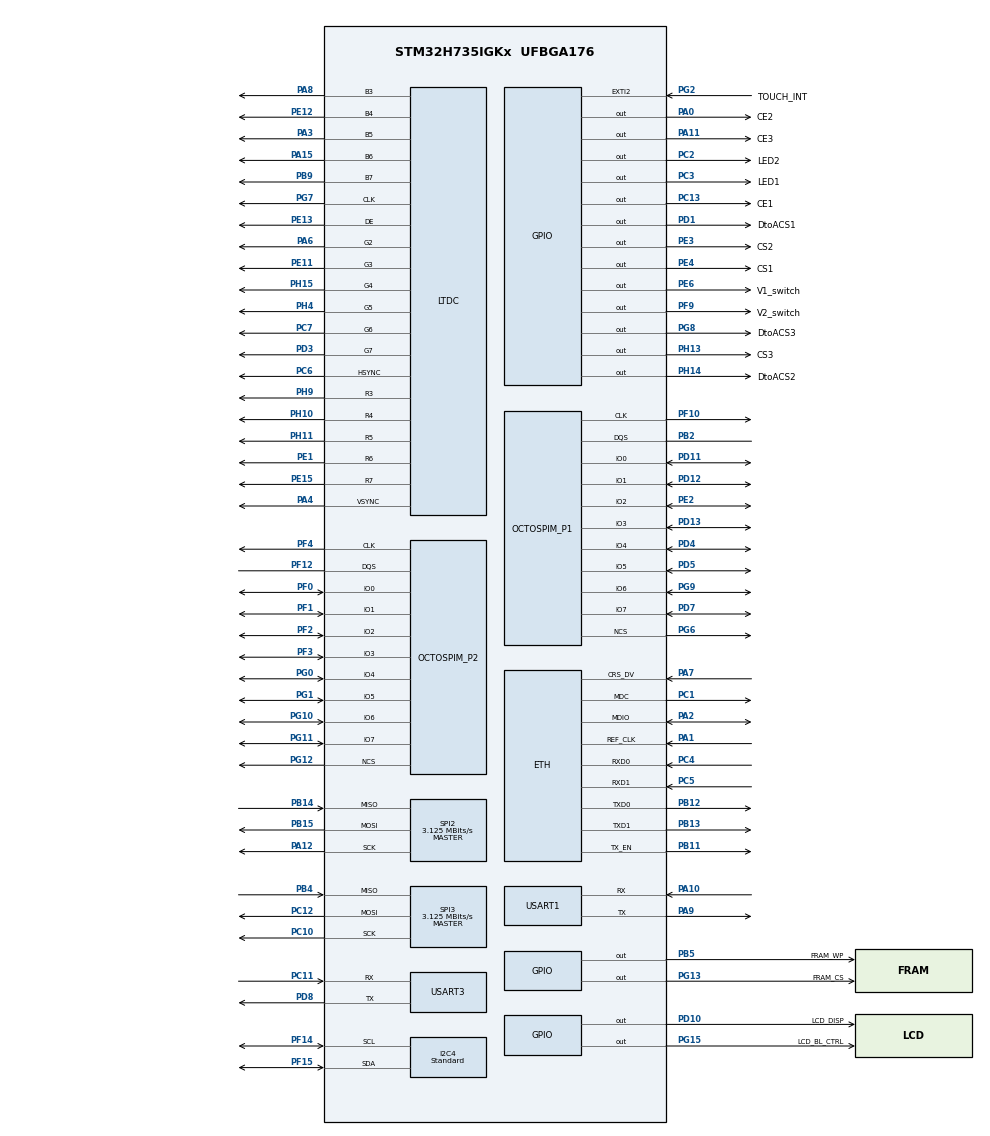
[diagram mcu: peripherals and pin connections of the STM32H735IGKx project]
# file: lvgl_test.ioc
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CORTEX_M7.AccessPermission-Cortex_Memory_Protection_Unit_Region1_Settings=MPU_REGION_FULL_ACCESS
CORTEX_M7.AccessPermission-Cortex_Memory_Protection_Unit_Region2_Settings=MPU_REGION_FULL_ACCESS
CORTEX_M7.BaseAddress-Cortex_Memory_Protection_Unit_Region1_Settings=0x30000000
CORTEX_M7.BaseAddress-Cortex_Memory_Protection_Unit_Region2_Settings=0x30000000
CORTEX_M7.CPU_DCache=Enabled
CORTEX_M7.CPU_ICache=Enabled
CORTEX_M7.DisableExec-Cortex_Memory_Protection_Unit_Region1_Settings=MPU_INSTRUCTION_ACCESS_DISABLE
CORTEX_M7.DisableExec-Cortex_Memory_Protection_Unit_Region2_Settings=MPU_INSTRUCTION_ACCESS_DISABLE
CORTEX_M7.Enable-Cortex_Memory_Protection_Unit_Region0_Settings=__NULL
CORTEX_M7.Enable-Cortex_Memory_Protection_Unit_Region1_Settings=MPU_REGION_ENABLE
CORTEX_M7.Enable-Cortex_Memory_Protection_Unit_Region2_Settings=MPU_REGION_ENABLE
CORTEX_M7.IsBufferable-Cortex_Memory_Protection_Unit_Region1_Settings=MPU_ACCESS_NOT_BUFFERABLE
CORTEX_M7.IsBufferable-Cortex_Memory_Protection_Unit_Region2_Settings=MPU_ACCESS_BUFFERABLE
CORTEX_M7.IsShareable-Cortex_Memory_Protection_Unit_Region1_Settings=MPU_ACCESS_NOT_SHAREABLE
CORTEX_M7.IsShareable-Cortex_Memory_Protection_Unit_Region2_Settings=MPU_ACCESS_SHAREABLE
CORTEX_M7.MPU_Control=MPU_PRIVILEGED_DEFAULT
CORTEX_M7.Size-Cortex_Memory_Protection_Unit_Region1_Settings=MPU_REGION_SIZE_32KB
CORTEX_M7.Size-Cortex_Memory_Protection_Unit_Region2_Settings=MPU_REGION_SIZE_512B
CORTEX_M7.TypeExtField-Cortex_Memory_Protection_Unit_Region1_Settings=MPU_TEX_LEVEL1
DMA2D.ColorMode=DMA2D_OUTPUT_RGB565
DMA2D.InputColorModeForeground=DMA2D_INPUT_RGB565
DMA2D.Mode=DMA2D_M2M
ETH.MediaInterface=HAL_ETH_RMII_MODE
ETH.RxBuffAddress=0x30000100
ETH.RxBuffLen=1536
ETH.TxDescAddress=0x30000100
FREERTOS.Tasks01=defaultTask,24,1024,StartDefaultTask,Default,NULL,Dynamic,NULL,NULL
FREERTOS.configTOTAL_HEAP_SIZE=100000
FREERTOS.configUSE_NEWLIB_REENTRANT=1
I2C4.I2C_Speed_Mode=I2C_Standard
I2C4.Timing=0x60404E72
LTDC.ActiveH=272
LTDC.ActiveW=480
LTDC.Alpha_L0=255
LTDC.FBStartAdress_L0=0x70000000
LTDC.HBP=13
LTDC.HFP=32
LTDC.HSync=41
LTDC.ImageHeight_L0=272
LTDC.ImageWidth_L0=480
LTDC.Layers=0
LTDC.PixelFormat_L0=LTDC_PIXEL_FORMAT_RGB565
LTDC.VSync=10
LTDC.WindowX1_L0=480
LTDC.WindowY1_L0=272
LWIP.BSP.number=1
LWIP.IP_ADDRESS=192.168.000.010
LWIP.LWIP_DHCP=0
LWIP.LWIP_RAM_HEAP_POINTER=0x30000200
LWIP.MEMP_NUM_TCP_SEG=17
LWIP.MEM_SIZE=32232
LWIP.NETMASK_ADDRESS=255.255.255.000
LWIP.TCP_MSS=1460
LWIP.TCP_SND_BUF=5840
LWIP.TCP_SND_QUEUELEN=17
LWIP.Version=v2.1.2_Cube
LWIP0.BSP.STBoard=false
LWIP0.BSP.api=BSP_COMPONENT_DRIVER
LWIP0.BSP.component=LAN8742
LWIP0.BSP.instance=LAN8742
LWIP0.BSP.name=Driver_PHY
LWIP0.BSP.solution=LAN8742
Mcu.Family=STM32H7
Mcu.Name=STM32H735IGKx
Mcu.Package=UFBGA176
NVIC.DMA2D_IRQn=true\:5\:0\:false\:false\:true\:true\:true\:true
NVIC.ETH_IRQn=true\:5\:0\:false\:false\:true\:true\:true\:true
NVIC.EXTI2_IRQn=true\:5\:0\:false\:false\:true\:true\:true\:true
NVIC.LTDC_IRQn=true\:5\:0\:false\:false\:true\:true\:true\:true
NVIC.PriorityGroup=NVIC_PRIORITYGROUP_4
NVIC.TIM6_DAC_IRQn=true\:15\:0\:false\:false\:true\:false\:false\:true
NVIC.TimeBase=TIM6_DAC_IRQn
NVIC.TimeBaseIP=TIM6
NVIC.USART1_IRQn=true\:5\:0\:false\:false\:true\:true\:true\:true
NVIC.USART3_IRQn=true\:5\:0\:false\:false\:true\:true\:true\:true
OCTOSPI1.ClockPrescaler=2
OCTOSPI1.FifoThreshold=4
OCTOSPI1.MemoryType=HAL_OSPI_MEMTYPE_MACRONIX
OCTOSPI2.AccessTime=6
OCTOSPI2.ChipSelectBoundary=23
OCTOSPI2.ChipSelectHighTime=4
OCTOSPI2.ClockPrescaler=2
OCTOSPI2.DelayBlockBypass=HAL_OSPI_DELAY_BLOCK_USED
OCTOSPI2.DelayHoldQuarterCycle=HAL_OSPI_DHQC_ENABLE
OCTOSPI2.DeviceSize=24
OCTOSPI2.FifoThreshold=4
OCTOSPI2.LatencyMode=HAL_OSPI_FIXED_LATENCY
OCTOSPI2.RWRecoveryTime=3
OCTOSPI2.Refresh=400
OCTOSPI2.WriteZeroLatency=HAL_OSPI_LATENCY_ON_WRITE
PA0.GPIO_Label=CE2
PA0.Signal=GPIO_Output
PA1.GPIO_Speed=GPIO_SPEED_FREQ_VERY_HIGH
PA1.Mode=RMII
PA1.Signal=ETH_REF_CLK
PA10.Mode=Asynchronous
PA10.Signal=USART1_RX
PA11.GPIO_Label=CE3
PA11.Signal=GPIO_Output
PA12.Mode=Full_Duplex_Master
PA12.Signal=SPI2_SCK
PA15(JTDI).Mode=RGB565
PA15(JTDI).Signal=LTDC_B6
PA2.GPIO_Speed=GPIO_SPEED_FREQ_VERY_HIGH
PA2.Mode=RMII
PA2.Signal=ETH_MDIO
PA3.Mode=RGB565
PA3.Signal=LTDC_B5
PA4.Mode=RGB565
PA4.Signal=LTDC_VSYNC
PA6.Mode=RGB565
PA6.Signal=LTDC_G2
PA7.GPIO_Speed=GPIO_SPEED_FREQ_VERY_HIGH
PA7.Mode=RMII
PA7.Signal=ETH_CRS_DV
PA8.Mode=RGB565
PA8.Signal=LTDC_B3
PA9.Mode=Asynchronous
PA9.Signal=USART1_TX
PB1.Signal=LTDC_G0
PB11.GPIO_Speed=GPIO_SPEED_FREQ_VERY_HIGH
PB11.Mode=RMII
PB11.Signal=ETH_TX_EN
PB12.GPIO_Speed=GPIO_SPEED_FREQ_VERY_HIGH
PB12.Mode=RMII
PB12.Signal=ETH_TXD0
PB13.GPIO_Speed=GPIO_SPEED_FREQ_VERY_HIGH
PB13.Mode=RMII
PB13.Signal=ETH_TXD1
PB14.Mode=Full_Duplex_Master
PB14.Signal=SPI2_MISO
PB15.Mode=Full_Duplex_Master
PB15.Signal=SPI2_MOSI
PB2.Mode=OCTOSPI1_Port1_DQS
PB2.Signal=OCTOSPIM_P1_DQS
PB4(NJTRST).GPIO_Speed=GPIO_SPEED_FREQ_VERY_HIGH
PB4(NJTRST).Mode=Full_Duplex_Master
PB4(NJTRST).Signal=SPI3_MISO
PB5.GPIO_Label=FRAM_WP
PB5.GPIO_PuPd=GPIO_PULLDOWN
PB5.Signal=GPIO_Output
PB9.Mode=RGB565
PB9.Signal=LTDC_B7
PC1.GPIO_Speed=GPIO_SPEED_FREQ_VERY_HIGH
PC1.Mode=RMII
PC1.Signal=ETH_MDC
PC10.GPIO_Speed=GPIO_SPEED_FREQ_VERY_HIGH
PC10.Mode=Full_Duplex_Master
PC10.Signal=SPI3_SCK
PC11.Mode=Asynchronous
PC11.Signal=USART3_RX
PC12.GPIO_Speed=GPIO_SPEED_FREQ_VERY_HIGH
PC12.Mode=Full_Duplex_Master
PC12.Signal=SPI3_MOSI
PC13.GPIO_Label=CE1
PC13.Signal=GPIO_Output
PC14-OSC32_IN.Mode=LSE-External-Oscillator
PC14-OSC32_IN.Signal=RCC_OSC32_IN
PC15-OSC32_OUT.Mode=LSE-External-Oscillator
PC15-OSC32_OUT.Signal=RCC_OSC32_OUT
PC2.GPIO_Label=LED2
PC2.Signal=GPIO_Output
PC3.GPIO_Label=LED1
PC3.Signal=GPIO_Output
PC4.GPIO_Speed=GPIO_SPEED_FREQ_VERY_HIGH
PC4.Mode=RMII
PC4.Signal=ETH_RXD0
PC5.GPIO_Speed=GPIO_SPEED_FREQ_VERY_HIGH
PC5.Mode=RMII
PC5.Signal=ETH_RXD1
PC6.Mode=RGB565
PC6.Signal=LTDC_HSYNC
PC7.Mode=RGB565
PC7.Signal=LTDC_G6
PD1.GPIO_Label=DtoACS1
PD1.Signal=GPIO_Output
PD10.GPIO_Label=LCD_DISP
PD10.Signal=GPIO_Output
PD11.Mode=OCTOSPI1_IOL_Port1L
PD11.Signal=OCTOSPIM_P1_IO0
PD12.Mode=OCTOSPI1_IOL_Port1L
PD12.Signal=OCTOSPIM_P1_IO1
PD13.Mode=OCTOSPI1_IOL_Port1L
PD13.Signal=OCTOSPIM_P1_IO3
PD3.Mode=RGB565
PD3.Signal=LTDC_G7
PD4.Mode=OCTOSPI1_IOH_Port1H
PD4.Signal=OCTOSPIM_P1_IO4
PD5.Mode=OCTOSPI1_IOH_Port1H
PD5.Signal=OCTOSPIM_P1_IO5
PD6.Signal=LTDC_B2
PD7.Mode=OCTOSPI1_IOH_Port1H
PD7.Signal=OCTOSPIM_P1_IO7
PD8.Mode=Asynchronous
PD8.Signal=USART3_TX
PE0.Signal=LTDC_R0
PE1.Mode=RGB565
PE1.Signal=LTDC_R6
PE11.Mode=RGB565
PE11.Signal=LTDC_G3
PE12.Mode=RGB565
PE12.Signal=LTDC_B4
PE13.Mode=RGB565
PE13.Signal=LTDC_DE
PE15.Mode=RGB565
PE15.Signal=LTDC_R7
PE2.Mode=OCTOSPI1_IOL_Port1L
PE2.Signal=OCTOSPIM_P1_IO2
PE3.GPIO_Label=CS2
PE3.Signal=GPIO_Output
PE4.GPIO_Label=CS1
PE4.Signal=GPIO_Output
PE6.GPIO_Label=V1_switch
PE6.Signal=GPIO_Output
PF0.Mode=OCTOSPI2_IOL_Port2L
PF0.Signal=OCTOSPIM_P2_IO0
PF1.Mode=OCTOSPI2_IOL_Port2L
PF1.Signal=OCTOSPIM_P2_IO1
PF10.Mode=O1_P1_CLK
PF10.Signal=OCTOSPIM_P1_CLK
PF12.Mode=OCTOSPI2_Port2_DQS
PF12.Signal=OCTOSPIM_P2_DQS
PF14.Mode=I2C
PF14.Signal=I2C4_SCL
PF15.Mode=I2C
PF15.Signal=I2C4_SDA
PF2.Mode=OCTOSPI2_IOL_Port2L
PF2.Signal=OCTOSPIM_P2_IO2
PF3.Mode=OCTOSPI2_IOL_Port2L
PF3.Signal=OCTOSPIM_P2_IO3
PF4.Mode=O2_P2_CLK
PF4.Signal=OCTOSPIM_P2_CLK
PF9.GPIO_Label=V2_switch
PF9.Signal=GPIO_Output
PG0.Mode=OCTOSPI2_IOH_Port2H
PG0.Signal=OCTOSPIM_P2_IO4
PG1.Mode=OCTOSPI2_IOH_Port2H
PG1.Signal=OCTOSPIM_P2_IO5
PG10.Mode=OCTOSPI2_IOH_Port2H
PG10.Signal=OCTOSPIM_P2_IO6
PG11.Mode=OCTOSPI2_IOH_Port2H
PG11.Signal=OCTOSPIM_P2_IO7
PG12.Mode=OCTOSPI2_Port2_NCS
PG12.Signal=OCTOSPIM_P2_NCS
PG13.GPIO_Label=FRAM_CS
PG13.Signal=GPIO_Output
PG15.GPIO_Label=LCD_BL_CTRL
PG15.Signal=GPIO_Output
PG2.GPIO_Label=TOUCH_INT
PG2.GPIO_ModeDefaultEXTI=GPIO_MODE_IT_RISING
PG2.Signal=GPXTI2
PG6.Mode=OCTOSPI1_Port1_NCS
PG6.Signal=OCTOSPIM_P1_NCS
PG7.Mode=RGB565
PG7.Signal=LTDC_CLK
PG8.GPIO_Label=DtoACS3
PG8.Signal=GPIO_Output
PG9.Mode=OCTOSPI1_IOH_Port1H
PG9.Signal=OCTOSPIM_P1_IO6
PH0-OSC_IN.Mode=HSE-External-Oscillator
PH0-OSC_IN.Signal=RCC_OSC_IN
PH1-OSC_OUT.Mode=HSE-External-Oscillator
PH1-OSC_OUT.Signal=RCC_OSC_OUT
PH10.Mode=RGB565
PH10.Signal=LTDC_R4
PH11.Mode=RGB565
PH11.Signal=LTDC_R5
PH13.GPIO_Label=CS3
PH13.Signal=GPIO_Output
PH14.GPIO_Label=DtoACS2
PH14.Signal=GPIO_Output
PH15.Mode=RGB565
PH15.Signal=LTDC_G4
PH4.Mode=RGB565
PH4.Signal=LTDC_G5
PH9.Mode=RGB565
PH9.Signal=LTDC_R3
ProjectManager.HeapSize=0x200
ProjectManager.StackSize=0x400
ProjectManager.TargetToolchain=STM32CubeIDE
RCC.ADCFreq_Value=200000000
RCC.APB1Freq_Value=137500000
RCC.APB2Freq_Value=137500000
RCC.APB3Freq_Value=137500000
RCC.APB4Freq_Value=137500000
RCC.CortexFreq_Value=550000000
RCC.D1PPRE=RCC_APB3_DIV2
RCC.D2PPRE1=RCC_APB1_DIV2
RCC.D2PPRE2=RCC_APB2_DIV2
RCC.D3PPRE=RCC_APB4_DIV2
RCC.DIVM1=2
RCC.DIVM2=5
RCC.DIVM3=25
RCC.DIVN1=44
RCC.DIVN2=80
RCC.DIVN3=288
RCC.DIVP1=1
RCC.DIVR3=30
RCC.HCLKFreq_Value=275000000
RCC.HPRE=RCC_HCLK_DIV2
RCC.PLLSourceVirtual=RCC_PLLSOURCE_HSE
RCC.SPI123CLockSelection=RCC_SPI123CLKSOURCE_PLL2
RCC.SYSCLKFreq_VALUE=550000000
RCC.SYSCLKSource=RCC_SYSCLKSOURCE_PLLCLK
RCC.USBFreq_Value=275000000
SPI2.BaudRatePrescaler=SPI_BAUDRATEPRESCALER_64
SPI2.CalculateBaudRate=3.125 MBits/s
SPI2.DataSize=SPI_DATASIZE_8BIT
SPI2.Direction=SPI_DIRECTION_2LINES
SPI2.Mode=SPI_MODE_MASTER
SPI2.VirtualType=VM_MASTER
SPI3.BaudRatePrescaler=SPI_BAUDRATEPRESCALER_64
SPI3.CLKPhase=SPI_PHASE_1EDGE
SPI3.CalculateBaudRate=3.125 MBits/s
SPI3.DataSize=SPI_DATASIZE_8BIT
SPI3.Direction=SPI_DIRECTION_2LINES
SPI3.Mode=SPI_MODE_MASTER
SPI3.VirtualType=VM_MASTER
STMicroelectronics.X-CUBE-TOUCHGFX.4.18.1.tgfx_address1=0x70000000
STMicroelectronics.X-CUBE-TOUCHGFX.4.18.1.tgfx_display_interface=disp_ltdc
STMicroelectronics.X-CUBE-TOUCHGFX.4.18.1.tgfx_location=By Address
STMicroelectronics.X-CUBE-TOUCHGFX.4.18.1.tgfx_vsync=vsync_ltdc
STMicroelectronics.X-CUBE-TOUCHGFX.4.18.1_IsPackSelfContextualization=true
USART1.VirtualMode-Asynchronous=VM_ASYNC
USART3.VirtualMode-Asynchronous=VM_ASYNC
VP_CRC_VS_CRC.Mode=CRC_Activate
VP_DMA2D_VS_DMA2D.Mode=DMA2D_Activate
VP_FREERTOS_VS_CMSIS_V2.Mode=CMSIS_V2
VP_LWIP_VS_Enabled.Mode=Enabled
VP_OCTOSPI1_VS_octo.Mode=octo_mode
VP_OCTOSPI2_VS_octo.Mode=hyperbus_mode
VP_SYS_VS_tim6.Mode=TIM6
board=custom

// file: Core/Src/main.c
/* USER CODE BEGIN Header */
/**
  ******************************************************************************
  * @file           : main.c
  * @brief          : Main program body
  ******************************************************************************
  * @attention
  *
  * Copyright (c) 2023 STMicroelectronics.
  * All rights reserved.
  *
  * This software is licensed under terms that can be found in the LICENSE file
  * in the root directory of this software component.
  * If no LICENSE file comes with this software, it is provided AS-IS.
  *
  ******************************************************************************
  */
/* USER CODE END Header */
#include "main.h"
#include "cmsis_os.h"
#include "lwip.h"

/* USER CODE BEGIN Includes */
#include "Init.h"
#include "string.h"
#include "stdio.h"
#include "stm32h735g_discovery_ospi.h"
#include "stm32h7xx_hal_ospi.h"
#include "ER-TPC050A2-2_GSL1680F_H.h"
#include "embedded_cli.h"
#include "ETH_server.h"
#include "ETH_DHCP.h"

/* USER CODE END Includes */

/* USER CODE BEGIN PTD */
#define EMBEDDED_CLI_IMPL
/* USER CODE END PTD */

CRC_HandleTypeDef hcrc;

DMA2D_HandleTypeDef hdma2d;

I2C_HandleTypeDef hi2c4;

LTDC_HandleTypeDef hltdc;

OSPI_HandleTypeDef hospi1;
OSPI_HandleTypeDef hospi2;

SPI_HandleTypeDef hspi2;
SPI_HandleTypeDef hspi3;

UART_HandleTypeDef huart1;
UART_HandleTypeDef huart3;

/* Definitions for defaultTask */
osThreadId_t defaultTaskHandle;
const osThreadAttr_t defaultTask_attributes = {
  .name = "defaultTask",
  .stack_size = 1024 * 4,
  .priority = (osPriority_t) osPriorityNormal,
};
/* USER CODE BEGIN PV */

extern uint8_t debounce;
char car;
/* USER CODE END PV */

void SystemClock_Config(void);
void PeriphCommonClock_Config(void);
static void MPU_Config(void);
static void MX_GPIO_Init(void);
static void MX_SPI2_Init(void);
static void MX_SPI3_Init(void);
static void MX_USART1_UART_Init(void);
static void MX_USART3_UART_Init(void);
static void MX_OCTOSPI1_Init(void);
static void MX_OCTOSPI2_Init(void);
static void MX_LTDC_Init(void);
static void MX_CRC_Init(void);
static void MX_I2C4_Init(void);
static void MX_DMA2D_Init(void);
void StartDefaultTask(void *argument);

/* USER CODE BEGIN PFP */
extern EmbeddedCli *cli;
#ifdef __GNUC__
/* With GCC, small printf (option LD Linker->Libraries->Small printf
   set to 'Yes') calls __io_putchar() */
#define PUTCHAR_PROTOTYPE int __io_putchar(int ch)
#else
#define PUTCHAR_PROTOTYPE int fputc(int ch, FILE *f)
#endif /* __GNUC__ */

//uint8_t* framebuffer=(uint8_t*)0x70000000;
//uint8_t* flashframebuffer=(uint8_t*)0x90000000;
//extern char image_aad[];
/* USER CODE END PFP */

int main(void)
{

  /* MPU Configuration--------------------------------------------------------*/
  MPU_Config();

  /* Enable I-Cache---------------------------------------------------------*/
  SCB_EnableICache();

  /* Enable D-Cache---------------------------------------------------------*/
  SCB_EnableDCache();

  /* MCU Configuration--------------------------------------------------------*/

  /* Reset of all peripherals, Initializes the Flash interface and the Systick. */
  HAL_Init();

  /* Configure the system clock */
  SystemClock_Config();

/* Configure the peripherals common clocks */
  PeriphCommonClock_Config();

  /* Initialize all configured peripherals */
  MX_GPIO_Init();
  MX_SPI2_Init();
  MX_SPI3_Init();
  MX_USART1_UART_Init();
  MX_USART3_UART_Init();
  MX_OCTOSPI1_Init();
  MX_OCTOSPI2_Init();
  MX_LTDC_Init();
  MX_CRC_Init();
  MX_I2C4_Init();
  MX_DMA2D_Init();
  /* USER CODE BEGIN 2 */
  Initialization();
  HAL_UART_Receive_IT(&huart1,(uint8_t*)&car,1);
  //HAL_LTDC_SetAddress(&hltdc, (uint32_t)flashframebuffer, LTDC_LAYER_1);
  //HAL_LTDC_SetAddress(&hltdc, (uint32_t)&image_aad[0], LTDC_LAYER_1);
  HAL_GPIO_WritePin(LCD_BL_CTRL_GPIO_Port,LCD_BL_CTRL_Pin,GPIO_PIN_SET);
  HAL_GPIO_WritePin(LCD_DISP_GPIO_Port,LCD_DISP_Pin,GPIO_PIN_SET);
  //memset(framebuffer,0xFF,480*272*24/8);

//  for (int i=0;i<480*272;i++)
//  {
//	  *framebuffer =0x00;  //blue
//	  framebuffer++;
//	  *framebuffer =0xFF;   //green
//	  framebuffer++;
//	  *framebuffer =0x00;  //red
//	  framebuffer++;
//	  //printf("address %x   data  %x\r\n",flashframebuffer,*flashframebuffer );
//	  framebuffer++;
//  }
  /* USER CODE END 2 */

  /* Init scheduler */
  osKernelInitialize();

  /* Create the thread(s) */
  /* creation of defaultTask */
  defaultTaskHandle = osThreadNew(StartDefaultTask, NULL, &defaultTask_attributes);

  /* Start scheduler */
  osKernelStart();

  /* We should never get here as control is now taken by the scheduler */
  /* Infinite loop */
  while (1)
  {

  }
}

void SystemClock_Config(void)
{
  RCC_OscInitTypeDef RCC_OscInitStruct = {0};
  RCC_ClkInitTypeDef RCC_ClkInitStruct = {0};

  /** Supply configuration update enable
  */
  HAL_PWREx_ConfigSupply(PWR_DIRECT_SMPS_SUPPLY);
  /** Configure the main internal regulator output voltage
  */
  __HAL_PWR_VOLTAGESCALING_CONFIG(PWR_REGULATOR_VOLTAGE_SCALE0);

  while(!__HAL_PWR_GET_FLAG(PWR_FLAG_VOSRDY)) {}
  /** Macro to configure the PLL clock source
  */
  __HAL_RCC_PLL_PLLSOURCE_CONFIG(RCC_PLLSOURCE_HSE);
  /** Initializes the RCC Oscillators according to the specified parameters
  * in the RCC_OscInitTypeDef structure.
  */
  RCC_OscInitStruct.OscillatorType = RCC_OSCILLATORTYPE_HSE;
  RCC_OscInitStruct.HSEState = RCC_HSE_ON;
  RCC_OscInitStruct.PLL.PLLState = RCC_PLL_ON;
  RCC_OscInitStruct.PLL.PLLSource = RCC_PLLSOURCE_HSE;
  RCC_OscInitStruct.PLL.PLLM = 2;
  RCC_OscInitStruct.PLL.PLLN = 44;
  RCC_OscInitStruct.PLL.PLLP = 1;
  RCC_OscInitStruct.PLL.PLLQ = 2;
  RCC_OscInitStruct.PLL.PLLR = 2;
  RCC_OscInitStruct.PLL.PLLRGE = RCC_PLL1VCIRANGE_3;
  RCC_OscInitStruct.PLL.PLLVCOSEL = RCC_PLL1VCOWIDE;
  RCC_OscInitStruct.PLL.PLLFRACN = 0;
  if (HAL_RCC_OscConfig(&RCC_OscInitStruct) != HAL_OK)
  {
    Error_Handler();
  }
  /** Initializes the CPU, AHB and APB buses clocks
  */
  RCC_ClkInitStruct.ClockType = RCC_CLOCKTYPE_HCLK|RCC_CLOCKTYPE_SYSCLK
                              |RCC_CLOCKTYPE_PCLK1|RCC_CLOCKTYPE_PCLK2
                              |RCC_CLOCKTYPE_D3PCLK1|RCC_CLOCKTYPE_D1PCLK1;
  RCC_ClkInitStruct.SYSCLKSource = RCC_SYSCLKSOURCE_PLLCLK;
  RCC_ClkInitStruct.SYSCLKDivider = RCC_SYSCLK_DIV1;
  RCC_ClkInitStruct.AHBCLKDivider = RCC_HCLK_DIV2;
  RCC_ClkInitStruct.APB3CLKDivider = RCC_APB3_DIV2;
  RCC_ClkInitStruct.APB1CLKDivider = RCC_APB1_DIV2;
  RCC_ClkInitStruct.APB2CLKDivider = RCC_APB2_DIV2;
  RCC_ClkInitStruct.APB4CLKDivider = RCC_APB4_DIV2;

  if (HAL_RCC_ClockConfig(&RCC_ClkInitStruct, FLASH_LATENCY_3) != HAL_OK)
  {
    Error_Handler();
  }
}

void PeriphCommonClock_Config(void)
{
  RCC_PeriphCLKInitTypeDef PeriphClkInitStruct = {0};

  /** Initializes the peripherals clock
  */
  PeriphClkInitStruct.PeriphClockSelection = RCC_PERIPHCLK_SPI3|RCC_PERIPHCLK_SPI2;
  PeriphClkInitStruct.PLL2.PLL2M = 5;
  PeriphClkInitStruct.PLL2.PLL2N = 80;
  PeriphClkInitStruct.PLL2.PLL2P = 2;
  PeriphClkInitStruct.PLL2.PLL2Q = 2;
  PeriphClkInitStruct.PLL2.PLL2R = 2;
  PeriphClkInitStruct.PLL2.PLL2RGE = RCC_PLL2VCIRANGE_2;
  PeriphClkInitStruct.PLL2.PLL2VCOSEL = RCC_PLL2VCOWIDE;
  PeriphClkInitStruct.PLL2.PLL2FRACN = 0;
  PeriphClkInitStruct.Spi123ClockSelection = RCC_SPI123CLKSOURCE_PLL2;
  if (HAL_RCCEx_PeriphCLKConfig(&PeriphClkInitStruct) != HAL_OK)
  {
    Error_Handler();
  }
}

static void MX_CRC_Init(void)
{

  hcrc.Instance = CRC;
  hcrc.Init.DefaultPolynomialUse = DEFAULT_POLYNOMIAL_ENABLE;
  hcrc.Init.DefaultInitValueUse = DEFAULT_INIT_VALUE_ENABLE;
  hcrc.Init.InputDataInversionMode = CRC_INPUTDATA_INVERSION_NONE;
  hcrc.Init.OutputDataInversionMode = CRC_OUTPUTDATA_INVERSION_DISABLE;
  hcrc.InputDataFormat = CRC_INPUTDATA_FORMAT_BYTES;
  if (HAL_CRC_Init(&hcrc) != HAL_OK)
  {
    Error_Handler();
  }

}

static void MX_DMA2D_Init(void)
{

  hdma2d.Instance = DMA2D;
  hdma2d.Init.Mode = DMA2D_M2M;
  hdma2d.Init.ColorMode = DMA2D_OUTPUT_RGB565;
  hdma2d.Init.OutputOffset = 0;
  hdma2d.LayerCfg[1].InputOffset = 0;
  hdma2d.LayerCfg[1].InputColorMode = DMA2D_INPUT_RGB565;
  hdma2d.LayerCfg[1].AlphaMode = DMA2D_NO_MODIF_ALPHA;
  hdma2d.LayerCfg[1].InputAlpha = 0;
  hdma2d.LayerCfg[1].AlphaInverted = DMA2D_REGULAR_ALPHA;
  hdma2d.LayerCfg[1].RedBlueSwap = DMA2D_RB_REGULAR;
  hdma2d.LayerCfg[1].ChromaSubSampling = DMA2D_NO_CSS;
  if (HAL_DMA2D_Init(&hdma2d) != HAL_OK)
  {
    Error_Handler();
  }
  if (HAL_DMA2D_ConfigLayer(&hdma2d, 1) != HAL_OK)
  {
    Error_Handler();
  }

}

static void MX_I2C4_Init(void)
{

  hi2c4.Instance = I2C4;
  hi2c4.Init.Timing = 0x60404E72;
  hi2c4.Init.OwnAddress1 = 0;
  hi2c4.Init.AddressingMode = I2C_ADDRESSINGMODE_7BIT;
  hi2c4.Init.DualAddressMode = I2C_DUALADDRESS_DISABLE;
  hi2c4.Init.OwnAddress2 = 0;
  hi2c4.Init.OwnAddress2Masks = I2C_OA2_NOMASK;
  hi2c4.Init.GeneralCallMode = I2C_GENERALCALL_DISABLE;
  hi2c4.Init.NoStretchMode = I2C_NOSTRETCH_DISABLE;
  if (HAL_I2C_Init(&hi2c4) != HAL_OK)
  {
    Error_Handler();
  }
  /** Configure Analogue filter
  */
  if (HAL_I2CEx_ConfigAnalogFilter(&hi2c4, I2C_ANALOGFILTER_ENABLE) != HAL_OK)
  {
    Error_Handler();
  }
  /** Configure Digital filter
  */
  if (HAL_I2CEx_ConfigDigitalFilter(&hi2c4, 0) != HAL_OK)
  {
    Error_Handler();
  }

}

static void MX_LTDC_Init(void)
{

  LTDC_LayerCfgTypeDef pLayerCfg = {0};

  hltdc.Instance = LTDC;
  hltdc.Init.HSPolarity = LTDC_HSPOLARITY_AL;
  hltdc.Init.VSPolarity = LTDC_VSPOLARITY_AL;
  hltdc.Init.DEPolarity = LTDC_DEPOLARITY_AL;
  hltdc.Init.PCPolarity = LTDC_PCPOLARITY_IPC;
  hltdc.Init.HorizontalSync = 40;
  hltdc.Init.VerticalSync = 9;
  hltdc.Init.AccumulatedHBP = 53;
  hltdc.Init.AccumulatedVBP = 11;
  hltdc.Init.AccumulatedActiveW = 533;
  hltdc.Init.AccumulatedActiveH = 283;
  hltdc.Init.TotalWidth = 565;
  hltdc.Init.TotalHeigh = 285;
  hltdc.Init.Backcolor.Blue = 0;
  hltdc.Init.Backcolor.Green = 0;
  hltdc.Init.Backcolor.Red = 0;
  if (HAL_LTDC_Init(&hltdc) != HAL_OK)
  {
    Error_Handler();
  }
  pLayerCfg.WindowX0 = 0;
  pLayerCfg.WindowX1 = 480;
  pLayerCfg.WindowY0 = 0;
  pLayerCfg.WindowY1 = 272;
  pLayerCfg.PixelFormat = LTDC_PIXEL_FORMAT_RGB565;
  pLayerCfg.Alpha = 255;
  pLayerCfg.Alpha0 = 0;
  pLayerCfg.BlendingFactor1 = LTDC_BLENDING_FACTOR1_CA;
  pLayerCfg.BlendingFactor2 = LTDC_BLENDING_FACTOR2_CA;
  pLayerCfg.FBStartAdress = 0x70000000;
  pLayerCfg.ImageWidth = 480;
  pLayerCfg.ImageHeight = 272;
  pLayerCfg.Backcolor.Blue = 0;
  pLayerCfg.Backcolor.Green = 0;
  pLayerCfg.Backcolor.Red = 0;
  if (HAL_LTDC_ConfigLayer(&hltdc, &pLayerCfg, 0) != HAL_OK)
  {
    Error_Handler();
  }

}

static void MX_OCTOSPI1_Init(void)
{

  /* USER CODE BEGIN OCTOSPI1_Init 0 */
	BSP_OSPI_NOR_Init_t ospi_nor_int;
  /* USER CODE END OCTOSPI1_Init 0 */

  OSPIM_CfgTypeDef sOspiManagerCfg = {0};

  /* OCTOSPI1 parameter configuration*/
  hospi1.Instance = OCTOSPI1;
  hospi1.Init.FifoThreshold = 4;
  hospi1.Init.DualQuad = HAL_OSPI_DUALQUAD_DISABLE;
  hospi1.Init.MemoryType = HAL_OSPI_MEMTYPE_MACRONIX;
  hospi1.Init.DeviceSize = 32;
  hospi1.Init.ChipSelectHighTime = 1;
  hospi1.Init.FreeRunningClock = HAL_OSPI_FREERUNCLK_DISABLE;
  hospi1.Init.ClockMode = HAL_OSPI_CLOCK_MODE_0;
  hospi1.Init.WrapSize = HAL_OSPI_WRAP_NOT_SUPPORTED;
  hospi1.Init.ClockPrescaler = 2;
  hospi1.Init.SampleShifting = HAL_OSPI_SAMPLE_SHIFTING_NONE;
  hospi1.Init.DelayHoldQuarterCycle = HAL_OSPI_DHQC_DISABLE;
  hospi1.Init.ChipSelectBoundary = 0;
  hospi1.Init.ClkChipSelectHighTime = 0;
  hospi1.Init.DelayBlockBypass = HAL_OSPI_DELAY_BLOCK_BYPASSED;
  hospi1.Init.MaxTran = 0;
  hospi1.Init.Refresh = 0;
  if (HAL_OSPI_Init(&hospi1) != HAL_OK)
  {
    Error_Handler();
  }
  sOspiManagerCfg.ClkPort = 1;
  sOspiManagerCfg.DQSPort = 1;
  sOspiManagerCfg.NCSPort = 1;
  sOspiManagerCfg.IOLowPort = HAL_OSPIM_IOPORT_1_LOW;
  sOspiManagerCfg.IOHighPort = HAL_OSPIM_IOPORT_1_HIGH;
  if (HAL_OSPIM_Config(&hospi1, &sOspiManagerCfg, HAL_OSPI_TIMEOUT_DEFAULT_VALUE) != HAL_OK)
  {
    Error_Handler();
  }
  /* USER CODE BEGIN OCTOSPI1_Init 2 */
  HAL_OSPI_DeInit(&hospi1);
  ospi_nor_int.InterfaceMode = BSP_OSPI_NOR_OPI_MODE;
  ospi_nor_int.TransferRate  = BSP_OSPI_NOR_DTR_TRANSFER;
  BSP_OSPI_NOR_DeInit(0);
  if(BSP_OSPI_NOR_Init(0, &ospi_nor_int) != BSP_ERROR_NONE)
  {
    Error_Handler();
  }
  if(BSP_OSPI_NOR_EnableMemoryMappedMode(0) != BSP_ERROR_NONE)
  {
    Error_Handler();
  }
  /* USER CODE END OCTOSPI1_Init 2 */

}

static void MX_OCTOSPI2_Init(void)
{

  OSPIM_CfgTypeDef sOspiManagerCfg = {0};
  OSPI_HyperbusCfgTypeDef sHyperBusCfg = {0};

  /* USER CODE BEGIN OCTOSPI2_Init 1 */
  OSPI_HyperbusCmdTypeDef sCommand = {0};
  OSPI_MemoryMappedTypeDef sMemMappedCfg = {0};
  /* USER CODE END OCTOSPI2_Init 1 */
  /* OCTOSPI2 parameter configuration*/
  hospi2.Instance = OCTOSPI2;
  hospi2.Init.FifoThreshold = 4;
  hospi2.Init.DualQuad = HAL_OSPI_DUALQUAD_DISABLE;
  hospi2.Init.MemoryType = HAL_OSPI_MEMTYPE_HYPERBUS;
  hospi2.Init.DeviceSize = 24;
  hospi2.Init.ChipSelectHighTime = 4;
  hospi2.Init.FreeRunningClock = HAL_OSPI_FREERUNCLK_DISABLE;
  hospi2.Init.ClockMode = HAL_OSPI_CLOCK_MODE_0;
  hospi2.Init.WrapSize = HAL_OSPI_WRAP_NOT_SUPPORTED;
  hospi2.Init.ClockPrescaler = 2;
  hospi2.Init.SampleShifting = HAL_OSPI_SAMPLE_SHIFTING_NONE;
  hospi2.Init.DelayHoldQuarterCycle = HAL_OSPI_DHQC_ENABLE;
  hospi2.Init.ChipSelectBoundary = 23;
  hospi2.Init.ClkChipSelectHighTime = 0;
  hospi2.Init.DelayBlockBypass = HAL_OSPI_DELAY_BLOCK_USED;
  hospi2.Init.MaxTran = 0;
  hospi2.Init.Refresh = 400;
  if (HAL_OSPI_Init(&hospi2) != HAL_OK)
  {
    Error_Handler();
  }
  sOspiManagerCfg.ClkPort = 2;
  sOspiManagerCfg.DQSPort = 2;
  sOspiManagerCfg.NCSPort = 2;
  sOspiManagerCfg.IOLowPort = HAL_OSPIM_IOPORT_2_LOW;
  sOspiManagerCfg.IOHighPort = HAL_OSPIM_IOPORT_2_HIGH;
  if (HAL_OSPIM_Config(&hospi2, &sOspiManagerCfg, HAL_OSPI_TIMEOUT_DEFAULT_VALUE) != HAL_OK)
  {
    Error_Handler();
  }
  sHyperBusCfg.RWRecoveryTime = 3;
  sHyperBusCfg.AccessTime = 6;
  sHyperBusCfg.WriteZeroLatency = HAL_OSPI_LATENCY_ON_WRITE;
  sHyperBusCfg.LatencyMode = HAL_OSPI_FIXED_LATENCY;
  if (HAL_OSPI_HyperbusCfg(&hospi2, &sHyperBusCfg, HAL_OSPI_TIMEOUT_DEFAULT_VALUE) != HAL_OK)
  {
    Error_Handler();
  }
  /* USER CODE BEGIN OCTOSPI2_Init 2 */
   sCommand.AddressSpace = HAL_OSPI_MEMORY_ADDRESS_SPACE;
   sCommand.AddressSize  = HAL_OSPI_ADDRESS_32_BITS;
   sCommand.DQSMode      = HAL_OSPI_DQS_ENABLE;
   sCommand.Address      = 0;
   sCommand.NbData       = 1;

   if (HAL_OSPI_HyperbusCmd(&hospi2, &sCommand, HAL_OSPI_TIMEOUT_DEFAULT_VALUE) != HAL_OK)
   {
     Error_Handler();
   }

   sMemMappedCfg.TimeOutActivation = HAL_OSPI_TIMEOUT_COUNTER_DISABLE;

   if (HAL_OSPI_MemoryMapped(&hospi2, &sMemMappedCfg) != HAL_OK)
   {
     Error_Handler();
   }
  /* USER CODE END OCTOSPI2_Init 2 */

}

static void MX_SPI2_Init(void)
{

  /* SPI2 parameter configuration*/
  hspi2.Instance = SPI2;
  hspi2.Init.Mode = SPI_MODE_MASTER;
  hspi2.Init.Direction = SPI_DIRECTION_2LINES;
  hspi2.Init.DataSize = SPI_DATASIZE_8BIT;
  hspi2.Init.CLKPolarity = SPI_POLARITY_LOW;
  hspi2.Init.CLKPhase = SPI_PHASE_1EDGE;
  hspi2.Init.NSS = SPI_NSS_SOFT;
  hspi2.Init.BaudRatePrescaler = SPI_BAUDRATEPRESCALER_64;
  hspi2.Init.FirstBit = SPI_FIRSTBIT_MSB;
  hspi2.Init.TIMode = SPI_TIMODE_DISABLE;
  hspi2.Init.CRCCalculation = SPI_CRCCALCULATION_DISABLE;
  hspi2.Init.CRCPolynomial = 0x0;
  hspi2.Init.NSSPMode = SPI_NSS_PULSE_ENABLE;
  hspi2.Init.NSSPolarity = SPI_NSS_POLARITY_LOW;
  hspi2.Init.FifoThreshold = SPI_FIFO_THRESHOLD_01DATA;
  hspi2.Init.TxCRCInitializationPattern = SPI_CRC_INITIALIZATION_ALL_ZERO_PATTERN;
  hspi2.Init.RxCRCInitializationPattern = SPI_CRC_INITIALIZATION_ALL_ZERO_PATTERN;
  hspi2.Init.MasterSSIdleness = SPI_MASTER_SS_IDLENESS_00CYCLE;
  hspi2.Init.MasterInterDataIdleness = SPI_MASTER_INTERDATA_IDLENESS_00CYCLE;
  hspi2.Init.MasterReceiverAutoSusp = SPI_MASTER_RX_AUTOSUSP_DISABLE;
  hspi2.Init.MasterKeepIOState = SPI_MASTER_KEEP_IO_STATE_DISABLE;
  hspi2.Init.IOSwap = SPI_IO_SWAP_DISABLE;
  if (HAL_SPI_Init(&hspi2) != HAL_OK)
  {
    Error_Handler();
  }

}

static void MX_SPI3_Init(void)
{

  /* SPI3 parameter configuration*/
  hspi3.Instance = SPI3;
  hspi3.Init.Mode = SPI_MODE_MASTER;
  hspi3.Init.Direction = SPI_DIRECTION_2LINES;
  hspi3.Init.DataSize = SPI_DATASIZE_8BIT;
  hspi3.Init.CLKPolarity = SPI_POLARITY_LOW;
  hspi3.Init.CLKPhase = SPI_PHASE_1EDGE;
  hspi3.Init.NSS = SPI_NSS_SOFT;
  hspi3.Init.BaudRatePrescaler = SPI_BAUDRATEPRESCALER_64;
  hspi3.Init.FirstBit = SPI_FIRSTBIT_MSB;
  hspi3.Init.TIMode = SPI_TIMODE_DISABLE;
  hspi3.Init.CRCCalculation = SPI_CRCCALCULATION_DISABLE;
  hspi3.Init.CRCPolynomial = 0x0;
  hspi3.Init.NSSPMode = SPI_NSS_PULSE_ENABLE;
  hspi3.Init.NSSPolarity = SPI_NSS_POLARITY_LOW;
  hspi3.Init.FifoThreshold = SPI_FIFO_THRESHOLD_01DATA;
  hspi3.Init.TxCRCInitializationPattern = SPI_CRC_INITIALIZATION_ALL_ZERO_PATTERN;
  hspi3.Init.RxCRCInitializationPattern = SPI_CRC_INITIALIZATION_ALL_ZERO_PATTERN;
  hspi3.Init.MasterSSIdleness = SPI_MASTER_SS_IDLENESS_00CYCLE;
  hspi3.Init.MasterInterDataIdleness = SPI_MASTER_INTERDATA_IDLENESS_00CYCLE;
  hspi3.Init.MasterReceiverAutoSusp = SPI_MASTER_RX_AUTOSUSP_DISABLE;
  hspi3.Init.MasterKeepIOState = SPI_MASTER_KEEP_IO_STATE_DISABLE;
  hspi3.Init.IOSwap = SPI_IO_SWAP_DISABLE;
  if (HAL_SPI_Init(&hspi3) != HAL_OK)
  {
    Error_Handler();
  }

}

static void MX_USART1_UART_Init(void)
{

  huart1.Instance = USART1;
  huart1.Init.BaudRate = 115200;
  huart1.Init.WordLength = UART_WORDLENGTH_8B;
  huart1.Init.StopBits = UART_STOPBITS_1;
  huart1.Init.Parity = UART_PARITY_NONE;
  huart1.Init.Mode = UART_MODE_TX_RX;
  huart1.Init.HwFlowCtl = UART_HWCONTROL_NONE;
  huart1.Init.OverSampling = UART_OVERSAMPLING_16;
  huart1.Init.OneBitSampling = UART_ONE_BIT_SAMPLE_DISABLE;
  huart1.Init.ClockPrescaler = UART_PRESCALER_DIV1;
  huart1.AdvancedInit.AdvFeatureInit = UART_ADVFEATURE_NO_INIT;
  if (HAL_UART_Init(&huart1) != HAL_OK)
  {
    Error_Handler();
  }
  if (HAL_UARTEx_SetTxFifoThreshold(&huart1, UART_TXFIFO_THRESHOLD_1_8) != HAL_OK)
  {
    Error_Handler();
  }
  if (HAL_UARTEx_SetRxFifoThreshold(&huart1, UART_RXFIFO_THRESHOLD_1_8) != HAL_OK)
  {
    Error_Handler();
  }
  if (HAL_UARTEx_DisableFifoMode(&huart1) != HAL_OK)
  {
    Error_Handler();
  }

}

static void MX_USART3_UART_Init(void)
{

  huart3.Instance = USART3;
  huart3.Init.BaudRate = 115200;
  huart3.Init.WordLength = UART_WORDLENGTH_8B;
  huart3.Init.StopBits = UART_STOPBITS_1;
  huart3.Init.Parity = UART_PARITY_NONE;
  huart3.Init.Mode = UART_MODE_TX_RX;
  huart3.Init.HwFlowCtl = UART_HWCONTROL_NONE;
  huart3.Init.OverSampling = UART_OVERSAMPLING_16;
  huart3.Init.OneBitSampling = UART_ONE_BIT_SAMPLE_DISABLE;
  huart3.Init.ClockPrescaler = UART_PRESCALER_DIV1;
  huart3.AdvancedInit.AdvFeatureInit = UART_ADVFEATURE_NO_INIT;
  if (HAL_UART_Init(&huart3) != HAL_OK)
  {
    Error_Handler();
  }
  if (HAL_UARTEx_SetTxFifoThreshold(&huart3, UART_TXFIFO_THRESHOLD_1_8) != HAL_OK)
  {
    Error_Handler();
  }
  if (HAL_UARTEx_SetRxFifoThreshold(&huart3, UART_RXFIFO_THRESHOLD_1_8) != HAL_OK)
  {
    Error_Handler();
  }
  if (HAL_UARTEx_DisableFifoMode(&huart3) != HAL_OK)
  {
    Error_Handler();
  }

}

static void MX_GPIO_Init(void)
{
  GPIO_InitTypeDef GPIO_InitStruct = {0};

  /* GPIO Ports Clock Enable */
  __HAL_RCC_GPIOG_CLK_ENABLE();
  __HAL_RCC_GPIOD_CLK_ENABLE();
  __HAL_RCC_GPIOA_CLK_ENABLE();
  __HAL_RCC_GPIOE_CLK_ENABLE();
  __HAL_RCC_GPIOB_CLK_ENABLE();
  __HAL_RCC_GPIOC_CLK_ENABLE();
  __HAL_RCC_GPIOH_CLK_ENABLE();
  __HAL_RCC_GPIOF_CLK_ENABLE();

  /*Configure GPIO pin Output Level */
  HAL_GPIO_WritePin(GPIOD, DtoACS1_Pin|LCD_DISP_Pin, GPIO_PIN_RESET);

  /*Configure GPIO pin Output Level */
  HAL_GPIO_WritePin(GPIOE, CS1_Pin|CS2_Pin|V1_switch_Pin, GPIO_PIN_RESET);

  /*Configure GPIO pin Output Level */
  HAL_GPIO_WritePin(GPIOG, FRAM_CS_Pin|LCD_BL_CTRL_Pin|DtoACS3_Pin, GPIO_PIN_RESET);

  /*Configure GPIO pin Output Level */
  HAL_GPIO_WritePin(GPIOH, DtoACS2_Pin|CS3_Pin, GPIO_PIN_RESET);

  /*Configure GPIO pin Output Level */
  HAL_GPIO_WritePin(GPIOC, CE1_Pin|LED2_Pin|LED1_Pin, GPIO_PIN_RESET);

  /*Configure GPIO pin Output Level */
  HAL_GPIO_WritePin(FRAM_WP_GPIO_Port, FRAM_WP_Pin, GPIO_PIN_RESET);

  /*Configure GPIO pin Output Level */
  HAL_GPIO_WritePin(GPIOA, CE3_Pin|CE2_Pin, GPIO_PIN_RESET);

  /*Configure GPIO pin Output Level */
  HAL_GPIO_WritePin(V2_switch_GPIO_Port, V2_switch_Pin, GPIO_PIN_RESET);

  /*Configure GPIO pins : DtoACS1_Pin LCD_DISP_Pin */
  GPIO_InitStruct.Pin = DtoACS1_Pin|LCD_DISP_Pin;
  GPIO_InitStruct.Mode = GPIO_MODE_OUTPUT_PP;
  GPIO_InitStruct.Pull = GPIO_NOPULL;
  GPIO_InitStruct.Speed = GPIO_SPEED_FREQ_LOW;
  HAL_GPIO_Init(GPIOD, &GPIO_InitStruct);

  /*Configure GPIO pins : CS1_Pin CS2_Pin V1_switch_Pin */
  GPIO_InitStruct.Pin = CS1_Pin|CS2_Pin|V1_switch_Pin;
  GPIO_InitStruct.Mode = GPIO_MODE_OUTPUT_PP;
  GPIO_InitStruct.Pull = GPIO_NOPULL;
  GPIO_InitStruct.Speed = GPIO_SPEED_FREQ_LOW;
  HAL_GPIO_Init(GPIOE, &GPIO_InitStruct);

  /*Configure GPIO pins : FRAM_CS_Pin LCD_BL_CTRL_Pin DtoACS3_Pin */
  GPIO_InitStruct.Pin = FRAM_CS_Pin|LCD_BL_CTRL_Pin|DtoACS3_Pin;
  GPIO_InitStruct.Mode = GPIO_MODE_OUTPUT_PP;
  GPIO_InitStruct.Pull = GPIO_NOPULL;
  GPIO_InitStruct.Speed = GPIO_SPEED_FREQ_LOW;
  HAL_GPIO_Init(GPIOG, &GPIO_InitStruct);

  /*Configure GPIO pins : DtoACS2_Pin CS3_Pin */
  GPIO_InitStruct.Pin = DtoACS2_Pin|CS3_Pin;
  GPIO_InitStruct.Mode = GPIO_MODE_OUTPUT_PP;
  GPIO_InitStruct.Pull = GPIO_NOPULL;
  GPIO_InitStruct.Speed = GPIO_SPEED_FREQ_LOW;
  HAL_GPIO_Init(GPIOH, &GPIO_InitStruct);

  /*Configure GPIO pins : CE1_Pin LED2_Pin LED1_Pin */
  GPIO_InitStruct.Pin = CE1_Pin|LED2_Pin|LED1_Pin;
  GPIO_InitStruct.Mode = GPIO_MODE_OUTPUT_PP;
  GPIO_InitStruct.Pull = GPIO_NOPULL;
  GPIO_InitStruct.Speed = GPIO_SPEED_FREQ_LOW;
  HAL_GPIO_Init(GPIOC, &GPIO_InitStruct);

  /*Configure GPIO pin : FRAM_WP_Pin */
  GPIO_InitStruct.Pin = FRAM_WP_Pin;
  GPIO_InitStruct.Mode = GPIO_MODE_OUTPUT_PP;
  GPIO_InitStruct.Pull = GPIO_PULLDOWN;
  GPIO_InitStruct.Speed = GPIO_SPEED_FREQ_LOW;
  HAL_GPIO_Init(FRAM_WP_GPIO_Port, &GPIO_InitStruct);

  /*Configure GPIO pins : CE3_Pin CE2_Pin */
  GPIO_InitStruct.Pin = CE3_Pin|CE2_Pin;
  GPIO_InitStruct.Mode = GPIO_MODE_OUTPUT_PP;
  GPIO_InitStruct.Pull = GPIO_NOPULL;
  GPIO_InitStruct.Speed = GPIO_SPEED_FREQ_LOW;
  HAL_GPIO_Init(GPIOA, &GPIO_InitStruct);

  /*Configure GPIO pin : TOUCH_INT_Pin */
  GPIO_InitStruct.Pin = TOUCH_INT_Pin;
  GPIO_InitStruct.Mode = GPIO_MODE_IT_RISING;
  GPIO_InitStruct.Pull = GPIO_NOPULL;
  HAL_GPIO_Init(TOUCH_INT_GPIO_Port, &GPIO_InitStruct);

  /*Configure GPIO pin : V2_switch_Pin */
  GPIO_InitStruct.Pin = V2_switch_Pin;
  GPIO_InitStruct.Mode = GPIO_MODE_OUTPUT_PP;
  GPIO_InitStruct.Pull = GPIO_NOPULL;
  GPIO_InitStruct.Speed = GPIO_SPEED_FREQ_LOW;
  HAL_GPIO_Init(V2_switch_GPIO_Port, &GPIO_InitStruct);

  /* EXTI interrupt init*/
  HAL_NVIC_SetPriority(EXTI2_IRQn, 5, 0);
  HAL_NVIC_EnableIRQ(EXTI2_IRQn);

}

/* USER CODE BEGIN 4 */
PUTCHAR_PROTOTYPE
{
/* Place your implementation of fputc here */
/* e.g. write a character to the USART1 and Loop until the end of transmission */
HAL_UART_Transmit(&huart1, (uint8_t *)&ch, 1, 0xFFFF);
return ch;
}

//void HAL_GPIO_EXTI_Callback (uint16_t GPIO_Pin)
//{
//	if( GPIO_Pin==TOUCH_INT_Pin)
//	{
//		debounce=1;
//	}
//}

void HAL_UART_RxCpltCallback(UART_HandleTypeDef *huart)
	{
		HAL_UART_Receive_IT(&huart1,(uint8_t*)&car,1);
		embeddedCliReceiveChar(cli, car);
	}
/* USER CODE END 4 */

void StartDefaultTask(void *argument)
{
  /* init code for LWIP */
  MX_LWIP_Init();
  /* USER CODE BEGIN 5 */
    LOCK_TCPIP_CORE();
    tcpserver_init();
    UNLOCK_TCPIP_CORE();
    DHCP_init();
  /* Infinite loop */
  for(;;)
  {
    osDelay(1);
  }
  /* USER CODE END 5 */
}

/* MPU Configuration */

void MPU_Config(void)
{
  MPU_Region_InitTypeDef MPU_InitStruct = {0};

  /* Disables the MPU */
  HAL_MPU_Disable();
  /** Initializes and configures the Region and the memory to be protected
  */
  MPU_InitStruct.Enable = MPU_REGION_ENABLE;
  MPU_InitStruct.Number = MPU_REGION_NUMBER1;
  MPU_InitStruct.BaseAddress = 0x30000000;
  MPU_InitStruct.Size = MPU_REGION_SIZE_32KB;
  MPU_InitStruct.SubRegionDisable = 0x0;
  MPU_InitStruct.TypeExtField = MPU_TEX_LEVEL1;
  MPU_InitStruct.AccessPermission = MPU_REGION_FULL_ACCESS;
  MPU_InitStruct.DisableExec = MPU_INSTRUCTION_ACCESS_DISABLE;
  MPU_InitStruct.IsShareable = MPU_ACCESS_NOT_SHAREABLE;
  MPU_InitStruct.IsCacheable = MPU_ACCESS_NOT_CACHEABLE;
  MPU_InitStruct.IsBufferable = MPU_ACCESS_NOT_BUFFERABLE;

  HAL_MPU_ConfigRegion(&MPU_InitStruct);
  /** Initializes and configures the Region and the memory to be protected
  */
  MPU_InitStruct.Number = MPU_REGION_NUMBER2;
  MPU_InitStruct.Size = MPU_REGION_SIZE_512B;
  MPU_InitStruct.TypeExtField = MPU_TEX_LEVEL0;
  MPU_InitStruct.IsShareable = MPU_ACCESS_SHAREABLE;
  MPU_InitStruct.IsBufferable = MPU_ACCESS_BUFFERABLE;

  HAL_MPU_ConfigRegion(&MPU_InitStruct);
  /* Enables the MPU */
  HAL_MPU_Enable(MPU_PRIVILEGED_DEFAULT);

}

void HAL_TIM_PeriodElapsedCallback(TIM_HandleTypeDef *htim)
{
  if (htim->Instance == TIM6) {
    HAL_IncTick();
  }
}

void Error_Handler(void)
{
  __disable_irq();
  while (1)
  {
  }
}
